# spi_master_apb_if: IP-XACT component
VLNV pulp-platform.org:peripheral:spi_master_apb_if:1.0

## Parameters
REG_STATUS = 4'b0000 — BASEREG + 0x00
REG_CLKDIV = 4'b0001 — BASEREG + 0x04
REG_SPICMD = 4'b0010 — BASEREG + 0x08
REG_SPIADR = 4'b0011 — BASEREG + 0x0C
REG_SPILEN = 4'b0100 — BASEREG + 0x10
REG_SPIDUM = 4'b0101 — BASEREG + 0x14
REG_TXFIFO = 4'b0110 — BASEREG + 0x18
REG_RXFIFO = 4'b1000 — BASEREG + 0x20
REG_INTCFG = 4'b1001 — BASEREG + 0x24
REG_INTSTA = 4'b1010 — BASEREG + 0x28
APB_ADDR_WIDTH = 12 — APB slaves are 4KB by default
BUFFER_DEPTH = 10
LOG_BUFFER_DEPTH = $clog2(BUFFER_DEPTH)

## Bus interfaces (logical=physical port)
apb: slave amba.com:AMBA3:APB:r1p0_4, memory map SPI
  PADDR=PADDR, PSELx[0:0]=PSEL[0:0], PENABLE[0:0]=PENABLE[0:0], PWRITE[0:0]=PWRITE[0:0], PRDATA=PRDATA, PWDATA=PWDATA, PREADY[0:0]=PREADY[0:0], PSLVERR[0:0]=PSLVERR[0:0]
rx: system pulp-platform.org:interface:fifo:1.0
  DATA=spi_data_rx, DATA_VALID=spi_data_rx_valid, FIFO_READY=spi_data_rx_ready
tx: system pulp-platform.org:interface:fifo:1.0
  DATA=spi_data_tx, DATA_VALID=spi_data_tx_valid, FIFO_READY=spi_data_tx_ready
spi_control: system pulp-platform.org:interface:spi_control:1.0
  SPI_CLK_DIV[7:0]=spi_clk_div[7:0], SPI_CLK_DIV_VALID[0:0]=spi_clk_div_valid[0:0], SPI_ADDR[31:0]=spi_addr[31:0], SPI_ADDR_LEN[5:0]=spi_addr_len[5:0], SPI_CMD[31:0]=spi_cmd[31:0], SPI_CMD_LEN[5:0]=spi_cmd_len[5:0], SPI_CSREG[3:0]=spi_csreg[3:0], SPI_DATA_LEN[15:0]=spi_data_len[15:0], SPI_DUMMY_RD[15:0]=spi_dummy_rd[15:0], SPI_DUMMY_WR[15:0]=spi_dummy_wr[15:0], SPI_SWRST[0:0]=spi_swrst[0:0], SPI_RD[0:0]=spi_rd[0:0], SPI_WR[0:0]=spi_wr[0:0], SPI_QRD[0:0]=spi_qrd[0:0], SPI_QWR[0:0]=spi_qwr[0:0]

## Ports
in HCLK
in HRESETn
in PADDR[APB_ADDR_WIDTH-1:0]
in PWDATA[31:0]
in PWRITE
in PSEL
in PENABLE
out PRDATA[31:0]
out PREADY
out PSLVERR
out spi_clk_div[7:0]
out spi_clk_div_valid
in spi_status[31:0]
out spi_addr[31:0]
out spi_addr_len[5:0]
out spi_cmd[31:0]
out spi_cmd_len[5:0]
out spi_csreg[3:0]
out spi_data_len[15:0]
out spi_dummy_rd[15:0]
out spi_dummy_wr[15:0]
out spi_int_th_tx[LOG_BUFFER_DEPTH:0]
out spi_int_th_rx[LOG_BUFFER_DEPTH:0]
out spi_int_cnt_tx[LOG_BUFFER_DEPTH:0]
out spi_int_cnt_rx[LOG_BUFFER_DEPTH:0]
out spi_int_en
out spi_int_cnt_en
out spi_int_rd_sta
out spi_swrst
out spi_rd
out spi_wr
out spi_qrd
out spi_qwr
out spi_data_tx[31:0]
out spi_data_tx_valid
in spi_data_tx_ready
in spi_data_rx[31:0]
in spi_data_rx_valid
out spi_data_rx_ready

## Address spaces and blocks
spimaster.spi_registers: base 'h0, range 'h28, width 32

## Registers
Registers are 32-bit, access not given, no defined reset value unless marked. A register's access mark holds for its fields unless they carry their own. Offsets are from the block's base; lines under a group give offsets from that group; [hi:lo] are bit positions; {n}, {i} and the like mark numbered series; 'fields as' and 'values as' point back to an identical list; <NAME> marks a mode.

## spimaster.spi_registers
Base 0x00000000
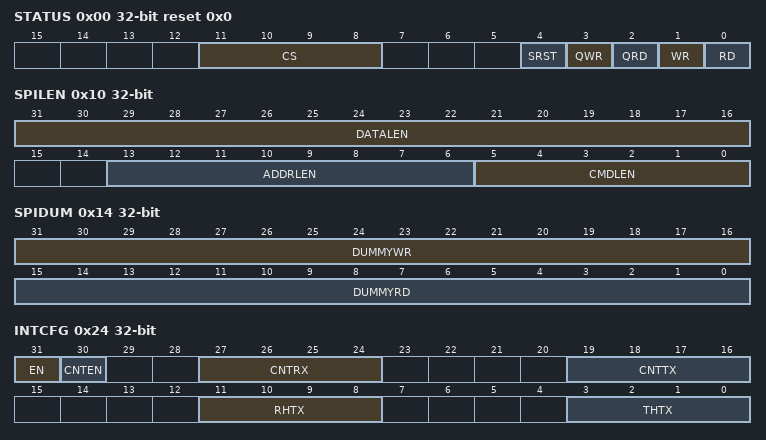
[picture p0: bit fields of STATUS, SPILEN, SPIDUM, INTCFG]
0x00 STATUS reset 0x0
  [11:8] CS, [4] SRST, [3] QWR, [2] QRD, [1] WR, [0] RD
0x04 CLKDIV
  [7:0] CLKDIV
0x08 SPICMD
0x0C SPIADR
0x10 SPILEN
  [31:16] DATALEN, [13:6] ADDRLEN, [5:0] CMDLEN
0x14 SPIDUM
  [31:16] DUMMYWR, [15:0] DUMMYRD
0x18 TXFIFO
  [31:0] TX
0x20 RXFIFO
  [31:0] RX
0x24 INTCFG
  [31] EN, [30] CNTEN, [27:24] CNTRX, [19:16] CNTTX, [11:8] RHTX, [3:0] THTX
